VERSION "NEO480_V1"

NS_ :

BS_:

BU_: CAN_RECEIVER H2OSensor

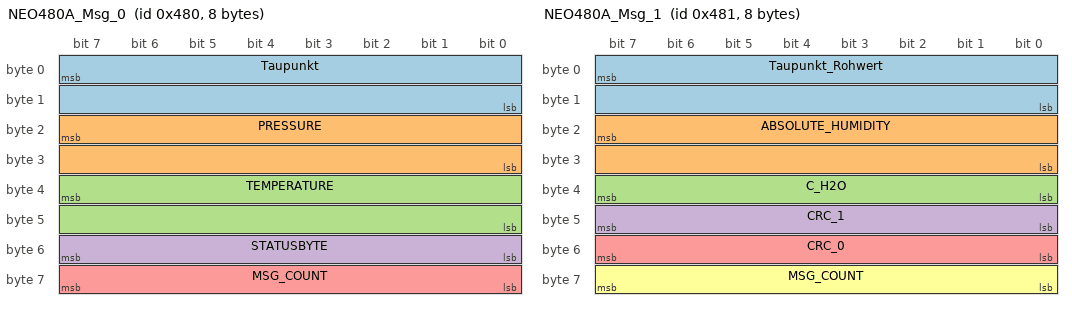
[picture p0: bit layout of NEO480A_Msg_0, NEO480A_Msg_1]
BO_ 1152 NEO480A_Msg_0: 8 H2OSensor
 SG_ Taupunkt : 7|16@0+ (0.01,-280.2) [-280|100] "C"  CAN_RECEIVER
 SG_ PRESSURE : 23|16@0+ (0.1,-2) [600|5000] "mbar"  CAN_RECEIVER
 SG_ TEMPERATURE : 39|16@0+ (0.01,-40.2) [-40|120] "C"  CAN_RECEIVER
 SG_ STATUSBYTE : 55|8@0+ (1,0) [0|255] "a.u."  CAN_RECEIVER
 SG_ MSG_COUNT : 63|8@0+ (1,0) [0|255] "a.u."  CAN_RECEIVER

BO_ 1153 NEO480A_Msg_1: 8 H2OSensor
 SG_ Taupunkt_Rohwert : 7|16@0+ (0.01,-280.2) [-280|100] "C"  CAN_RECEIVER
 SG_ ABSOLUTE_HUMIDITY : 23|16@0+ (0.01,-0.2) [0|440] "g/m3"  CAN_RECEIVER
 SG_ C_H2O : 39|8@0+ (0.5,-10) [0|100] "Vol.-%"  CAN_RECEIVER
 SG_ CRC_1 : 47|8@0+ (1,0) [0|255] "a.u."  CAN_RECEIVER
 SG_ CRC_0: 55|8@0+ (1,0) [0|255] "a.u."  CAN_RECEIVER
 SG_ MSG_COUNT : 63|8@0+ (1,0) [0|255] "a.u."  CAN_RECEIVER

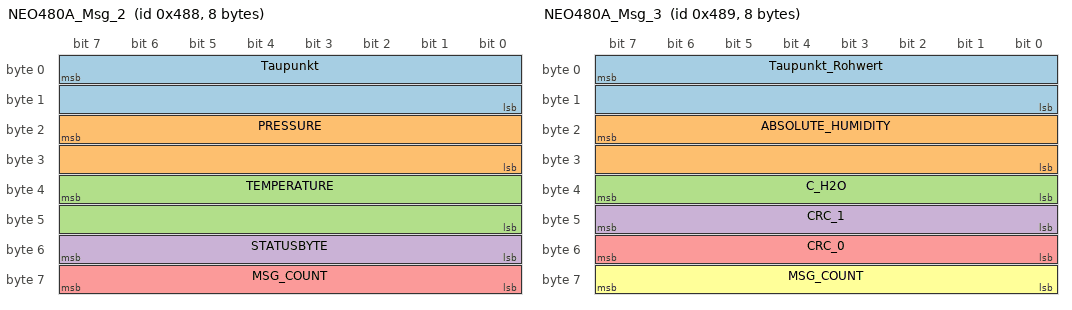
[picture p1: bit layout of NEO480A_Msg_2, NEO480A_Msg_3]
BO_ 1160 NEO480A_Msg_2: 8 H2OSensor
 SG_ Taupunkt : 7|16@0+ (0.01,-280.2) [-280|100] "C"  CAN_RECEIVER
 SG_ PRESSURE : 23|16@0+ (0.1,-2) [600|5000] "mbar"  CAN_RECEIVER
 SG_ TEMPERATURE : 39|16@0+ (0.01,-40.2) [-40|120] "C"  CAN_RECEIVER
 SG_ STATUSBYTE : 55|8@0+ (1,0) [0|255] "a.u."  CAN_RECEIVER
 SG_ MSG_COUNT : 63|8@0+ (1,0) [0|255] "a.u."  CAN_RECEIVER

BO_ 1161 NEO480A_Msg_3: 8 H2OSensor
 SG_ Taupunkt_Rohwert : 7|16@0+ (0.01,-280.2) [-280|100] "C"  CAN_RECEIVER
 SG_ ABSOLUTE_HUMIDITY : 23|16@0+ (0.01,-0.2) [0|440] "g/m3"  CAN_RECEIVER
 SG_ C_H2O : 39|8@0+ (0.5,-10) [0|100] "Vol.-%"  CAN_RECEIVER
 SG_ CRC_1 : 47|8@0+ (1,0) [0|255] "a.u."  CAN_RECEIVER
 SG_ CRC_0: 55|8@0+ (1,0) [0|255] "a.u."  CAN_RECEIVER
 SG_ MSG_COUNT : 63|8@0+ (1,0) [0|255] "a.u."  CAN_RECEIVER

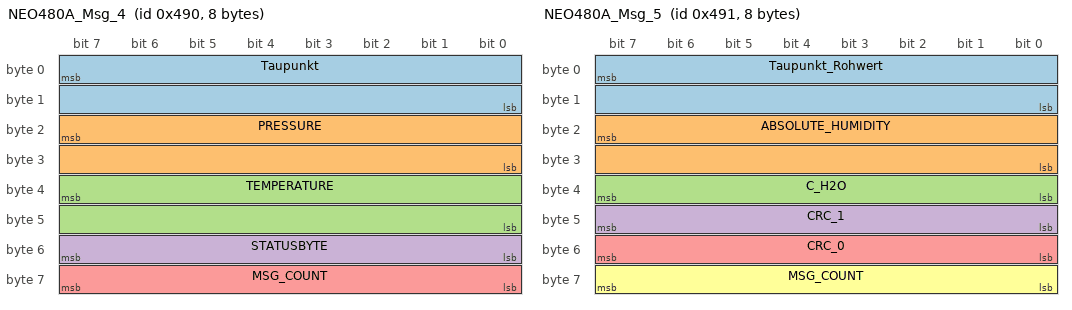
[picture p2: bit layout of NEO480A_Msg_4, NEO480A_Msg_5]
BO_ 1168 NEO480A_Msg_4: 8 H2OSensor
 SG_ Taupunkt : 7|16@0+ (0.01,-280.2) [-280|100] "C"  CAN_RECEIVER
 SG_ PRESSURE : 23|16@0+ (0.1,-2) [600|5000] "mbar"  CAN_RECEIVER
 SG_ TEMPERATURE : 39|16@0+ (0.01,-40.2) [-40|120] "C"  CAN_RECEIVER
 SG_ STATUSBYTE : 55|8@0+ (1,0) [0|255] "a.u."  CAN_RECEIVER
 SG_ MSG_COUNT : 63|8@0+ (1,0) [0|255] "a.u."  CAN_RECEIVER

BO_ 1169 NEO480A_Msg_5: 8 H2OSensor
 SG_ Taupunkt_Rohwert : 7|16@0+ (0.01,-280.2) [-280|100] "C"  CAN_RECEIVER
 SG_ ABSOLUTE_HUMIDITY : 23|16@0+ (0.01,-0.2) [0|440] "g/m3"  CAN_RECEIVER
 SG_ C_H2O : 39|8@0+ (0.5,-10) [0|100] "Vol.-%"  CAN_RECEIVER
 SG_ CRC_1 : 47|8@0+ (1,0) [0|255] "a.u."  CAN_RECEIVER
 SG_ CRC_0: 55|8@0+ (1,0) [0|255] "a.u."  CAN_RECEIVER
 SG_ MSG_COUNT : 63|8@0+ (1,0) [0|255] "a.u."  CAN_RECEIVER

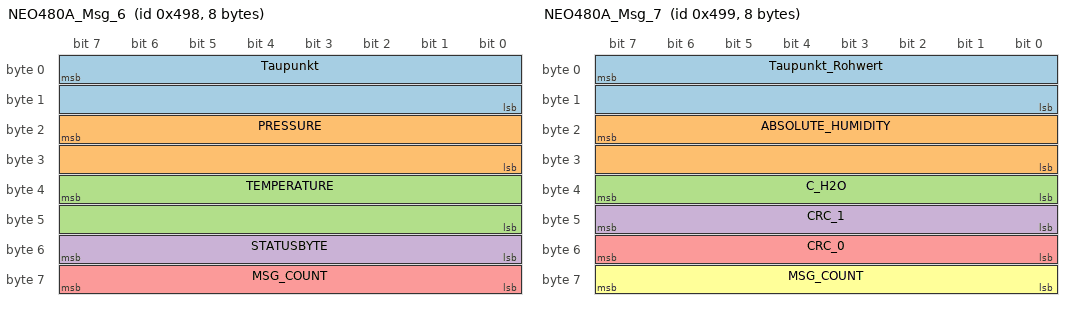
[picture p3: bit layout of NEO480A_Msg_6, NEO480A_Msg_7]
BO_ 1176 NEO480A_Msg_6: 8 H2OSensor
 SG_ Taupunkt : 7|16@0+ (0.01,-280.2) [-280|100] "C"  CAN_RECEIVER
 SG_ PRESSURE : 23|16@0+ (0.1,-2) [600|5000] "mbar"  CAN_RECEIVER
 SG_ TEMPERATURE : 39|16@0+ (0.01,-40.2) [-40|120] "C"  CAN_RECEIVER
 SG_ STATUSBYTE : 55|8@0+ (1,0) [0|255] "a.u."  CAN_RECEIVER
 SG_ MSG_COUNT : 63|8@0+ (1,0) [0|255] "a.u."  CAN_RECEIVER

BO_ 1177 NEO480A_Msg_7: 8 H2OSensor
 SG_ Taupunkt_Rohwert : 7|16@0+ (0.01,-280.2) [-280|100] "C"  CAN_RECEIVER
 SG_ ABSOLUTE_HUMIDITY : 23|16@0+ (0.01,-0.2) [0|440] "g/m3"  CAN_RECEIVER
 SG_ C_H2O : 39|8@0+ (0.5,-10) [0|100] "Vol.-%"  CAN_RECEIVER
 SG_ CRC_1 : 47|8@0+ (1,0) [0|255] "a.u."  CAN_RECEIVER
 SG_ CRC_0: 55|8@0+ (1,0) [0|255] "a.u."  CAN_RECEIVER
 SG_ MSG_COUNT : 63|8@0+ (1,0) [0|255] "a.u."  CAN_RECEIVER

BA_DEF_  "BusType" STRING ;
BA_DEF_DEF_  "BusType" "CAN";
